VERSION ""

NS_ :

BS_:
BU_: VCU PDU CCU PCU ZCU BMS

// if the prototype battery
BO_ 512 COMMAND_FRAME_BMS: 8 VCU
  SG_ VCU_STATE_REQUEST : 5|3@1+ (1,0) [0|7] "" BMS

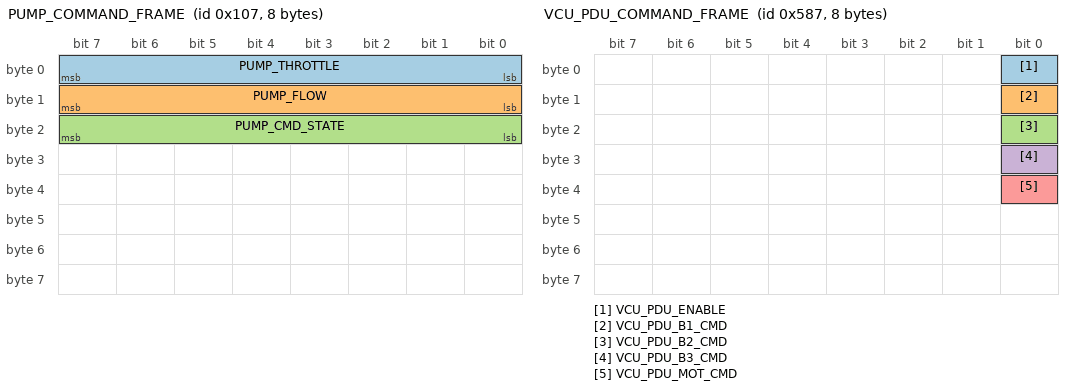
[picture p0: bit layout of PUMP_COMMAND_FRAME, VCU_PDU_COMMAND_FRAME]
BO_ 263 PUMP_COMMAND_FRAME: 8 VCU
 SG_ PUMP_THROTTLE : 0|8@1+ (1,0) [0|100] "%"  VCU
 SG_ PUMP_FLOW : 8|8@1+ (0.1,0) [0|25.5] "L/min"  VCU
 SG_ PUMP_CMD_STATE : 16|8@1+ (1,0) [0|255] ""  VCU

// if the production battery
BO_ 1264 COMMAND_FRAME_BMS: 8 VCU
  SG_ VCU_STATE_REQUEST : 5|3@1+ (1,0) [0|7] "" BMS

BO_ 1415 VCU_PDU_COMMAND_FRAME: 8 VCU
  SG_ VCU_PDU_ENABLE : 0|1@0+ (1,0) [0|1] "" PDU
  SG_ VCU_PDU_B1_CMD : 8|1@0+ (1,0) [0|1] "" PDU
  SG_ VCU_PDU_B2_CMD : 16|1@0+ (1,0) [0|1] "" PDU
  SG_ VCU_PDU_B3_CMD : 24|1@0+ (1,0) [0|1] "" PDU
  SG_ VCU_PDU_MOT_CMD : 32|1@0+ (1,0) [0|1] "" PDU

BO_ 1543 CCU_ZCU_COMMAND_FRAME: 8 VCU
 SG_ CCU_CMD : 0|8@1+ (1,0) [0|1] ""  VCU

BO_ 1831 VCU_PCU_COMMAND_FRAME: 8 VCU
 SG_ VCU_PCU_DERATING_MODE : 0|1@1+ (1,0) [0|1] ""  PCU
 SG_ VCU_PCU_MAINTENANCE_MODE : 1|1@1+ (1,0) [0|1] ""  PCU
 SG_ VCU_PCU_MODE_ECO_SPORT : 2|1@1+ (1,0) [0|1] ""  PCU
 SG_ VCU_PCU_BOOST_MODE : 3|1@1+ (1,0) [0|1] ""  PCU
 SG_ VCU_PCU_BIST_mode : 4|1@1+ (1,0) [0|1] ""  PCU
 SG_ VCU_PCU_BRAKE : 5|1@1+ (1,0) [0|1] ""  PCU
 SG_ VCU_PCU_MODE_START_STOP : 6|1@1+ (1,0) [0|1] ""  PCU
 SG_ VCU_PCU_FORCED_MODE : 7|1@1+ (1,0) [0|1] ""  PCU
 SG_ VCU_PCU_CTRL_FORCEDPUMP : 8|4@1+ (1,0) [0|15] ""  PCU
 SG_ VCU_PCU_TRIM_DOWN_COMMAND : 12|1@1+ (1,0) [0|1] ""  PCU
 SG_ VCU_PCU_TRIM_UP_COMMAND : 13|1@1+ (1,0) [0|1] ""  PCU
 SG_ VCU_PCU_CTRL_JAKETRIM_SEL : 14|1@1+ (1,0) [0|1] ""  PCU
 SG_ VCU_PCU_LED : 15|1@1+ (1,0) [0|1] ""  PCU
 SG_ VCU_PCU_THROTTLE : 16|7@1+ (1,0) [0|100] "%"  PCU
 SG_ VCU_PCU_WATER_DETECTED : 23|1@1+ (1,0) [0|1] ""  PCU
 SG_ VCU_PCU_DRIVE_SELECT : 24|4@1+ (1,0) [0|15] ""  PCU
 SG_ VCU_PCU_IGN : 28|1@1+ (1,0) [0|1] ""  PCU
 SG_ VCU_PCU_DRIVE_CHARGE_STATE : 29|1@1+ (1,0) [0|1] ""  PCU
 SG_ VCU_PCU_kill : 30|1@1+ (1,0) [0|1] ""  PCU
 SG_ VCU_PCU_HVIL : 31|1@1+ (1,0) [0|1] ""  PCU
 SG_ VCU_PCU_UV_LIMIT : 32|16@1+ (0.1,0) [0|6553.5] "V"  PCU
 SG_ VCU_PCU_MAXCUR_LIMIT : 48|16@1+ (1,0) [0|65535] "A"  PCU

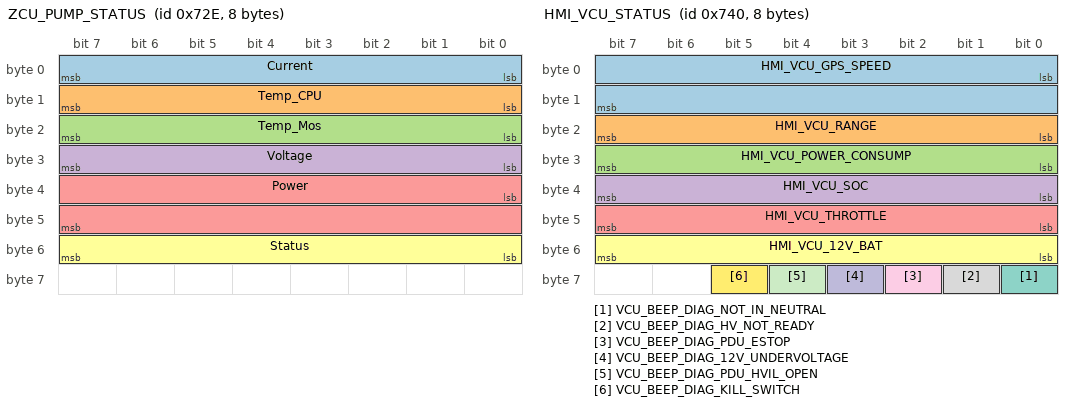
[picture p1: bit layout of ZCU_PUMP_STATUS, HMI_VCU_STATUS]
BO_ 1838 ZCU_PUMP_STATUS: 8 ZCU
 SG_ Current : 0|8@1+ (0.2,0) [0|50.8] "A" Vector__XXX
 SG_ Temp_CPU : 8|8@1+ (1,40) [-40|215] "°C" Vector__XXX
 SG_ Temp_Mos : 16|8@1+ (1,40) [-40|215] "°C" Vector__XXX
 SG_ Voltage : 24|8@1+ (0.1,0) [0|25.5] "V" Vector__XXX
 SG_ Power : 32|16@1+ (0.1,0) [0|6553.5] "W" Vector__XXX
 SG_ Status : 48|8@1+ (1,0) [0|255] "" Vector__XXX

BO_ 1856 HMI_VCU_STATUS: 8 VCU
  SG_ HMI_VCU_GPS_SPEED : 0|16@1+ (0.02302,0) [0|100] "MPH" Vector__XXX
  SG_ HMI_VCU_RANGE : 16|8@1+ (1,0) [0|300] "NM" Vector__XXX
  SG_ HMI_VCU_POWER_CONSUMP : 24|8@1+ (0.1,0) [-500|500] "kW" Vector__XXX
  SG_ HMI_VCU_SOC : 32|8@1+ (1,0) [0|100] "%" Vector__XXX
  SG_ HMI_VCU_THROTTLE : 40|8@1+ (1,0) [0|100] "%" Vector__XXX
  SG_ HMI_VCU_12V_BAT : 48|8@1+ (0.1,0) [0|15] "VDC" Vector__XXX
  SG_ VCU_BEEP_DIAG_NOT_IN_NEUTRAL : 56|1@1+ (1,0) [0|1] "" Vector__XXX
  SG_ VCU_BEEP_DIAG_HV_NOT_READY : 57|1@1+ (1,0) [0|1] "" Vector__XXX
  SG_ VCU_BEEP_DIAG_PDU_ESTOP : 58|1@1+ (1,0) [0|1] "" Vector__XXX
  SG_ VCU_BEEP_DIAG_12V_UNDERVOLTAGE : 59|1@1+ (1,0) [0|1] "" Vector__XXX
  SG_ VCU_BEEP_DIAG_PDU_HVIL_OPEN : 60|1@1+ (1,0) [0|1] "" Vector__XXX
  SG_ VCU_BEEP_DIAG_KILL_SWITCH : 61|1@1+ (1,0) [0|1] "" Vector__XXX

BO_ 1408 PDU_RELAY_STATUS: 8 PDU
  SG_ PDU_B1_NEG_CMD          :  0|1@1+ (1,0) [0|1] "" VCU
  SG_ PDU_B1_NEG_STATUS       :  3|1@1+ (1,0) [0|1] "" VCU
  SG_ PDU_B1_POS_CMD          :  4|1@1+ (1,0) [0|1] "" VCU
  SG_ PDU_B1_POS_STATUS       :  7|1@1+ (1,0) [0|1] "" VCU
  SG_ PDU_B2_NEG_CMD          :  8|1@1+ (1,0) [0|1] "" VCU
  SG_ PDU_B2_NEG_STATUS       : 11|1@1+ (1,0) [0|1] "" VCU
  SG_ PDU_B2_POS_CMD          : 12|1@1+ (1,0) [0|1] "" VCU
  SG_ PDU_B2_POS_STATUS       : 15|1@1+ (1,0) [0|1] "" VCU
  SG_ PDU_B3_NEG_CMD          : 16|1@1+ (1,0) [0|1] "" VCU
  SG_ PDU_B3_NEG_STATUS       : 19|1@1+ (1,0) [0|1] "" VCU
  SG_ PDU_B3_POS_CMD          : 20|1@1+ (1,0) [0|1] "" VCU
  SG_ PDU_B3_POS_STATUS       : 23|1@1+ (1,0) [0|1] "" VCU
  SG_ PDU_MOT_NEG_CMD         : 24|1@1+ (1,0) [0|1] "" VCU
  SG_ PDU  PDU_MOT_NEG_STATUS  : 27|1@1+ (1,0) [0|1] "" VCU
  SG_ PDU_MOT_POS_CMD         : 28|1@1+ (1,0) [0|1] "" VCU
  SG_ PDU_MOT_POS_STATUS      : 31|1@1+ (1,0) [0|1] "" VCU
  SG_ PDU_PRECHG_CMD          : 44|1@1+ (1,0) [0|1] "" VCU
  SG_ PDU_MSG_COUNTER         : 56|8@1+ (1,0) [0|255] "" VCU

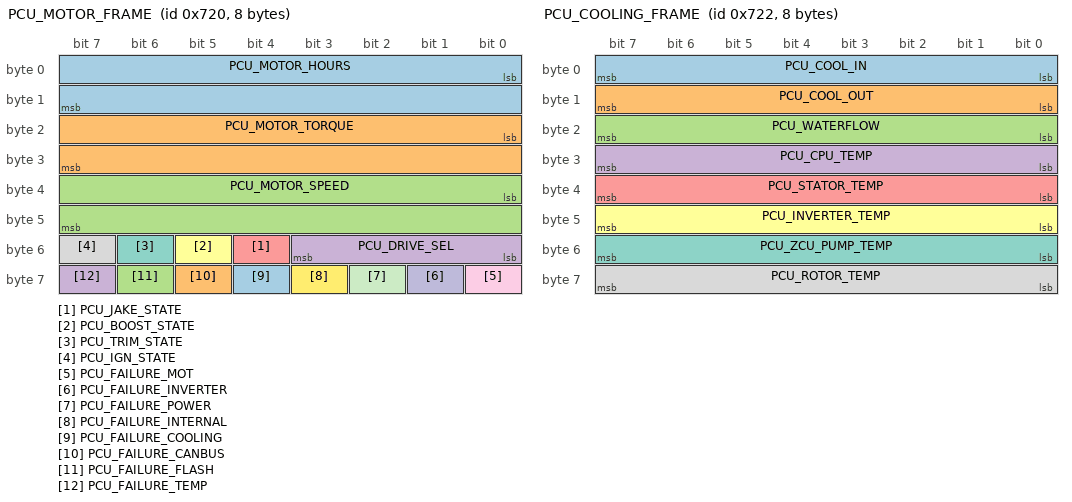
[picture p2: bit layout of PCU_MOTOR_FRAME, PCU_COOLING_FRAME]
BO_ 1824 PCU_MOTOR_FRAME: 8 PCU
  SG_ PCU_MOTOR_HOURS : 0|16@1+ (1,0) [0|10000] "h" VCU
  SG_ PCU_MOTOR_TORQUE : 16|16@1- (0.1,0) [-30000|30000] "Nm" VCU
  SG_ PCU_MOTOR_SPEED : 32|16@1+ (1,0) [0|30000] "RPM" VCU
  SG_ PCU_DRIVE_SEL : 48|4@1+ (1,0) [0|15] "" VCU
  SG_ PCU_JAKE_STATE : 52|1@1+ (1,0) [0|1] "" VCU
  SG_ PCU_BOOST_STATE : 53|1@1+ (1,0) [0|1] "" VCU
  SG_ PCU_TRIM_STATE : 54|1@1+ (1,0) [0|1] "" VCU
  SG_ PCU_IGN_STATE : 55|1@1+ (1,0) [0|1] "" VCU
  SG_ PCU_FAILURE_MOT : 56|1@1+ (1,0) [0|1] "" VCU
  SG_ PCU_FAILURE_INVERTER : 57|1@1+ (1,0) [0|1] "" VCU
  SG_ PCU_FAILURE_POWER : 58|1@1+ (1,0) [0|1] "" VCU
  SG_ PCU_FAILURE_INTERNAL : 59|1@1+ (1,0) [0|1] "" VCU
  SG_ PCU_FAILURE_COOLING : 60|1@1+ (1,0) [0|1] "" VCU
  SG_ PCU_FAILURE_CANBUS : 61|1@1+ (1,0) [0|1] "" VCU
  SG_ PCU_FAILURE_FLASH : 62|1@1+ (1,0) [0|1] "" VCU
  SG_ PCU_FAILURE_TEMP : 63|1@1+ (1,0) [0|1] "" VCU

BO_ 1826 PCU_COOLING_FRAME: 8 PCU
  SG_ PCU_COOL_IN : 0|8@1+ (1,-40) [-40|215] "Celcius" VCU
  SG_ PCU_COOL_OUT : 8|8@1+ (1,-40) [-40|215] "Celcius" VCU
  SG_ PCU_WATERFLOW : 16|8@1+ (0.1,0) [0|25.5] "LPM" VCU
  SG_ PCU_CPU_TEMP : 24|8@1+ (1,-40) [-40|215] "Celcius" VCU
  SG_ PCU_STATOR_TEMP : 32|8@1+ (1,-40) [-40|215] "Celcius" VCU
  SG_ PCU_INVERTER_TEMP : 40|8@1+ (1,-40) [-40|215] "Celcius" VCU
  SG_ PCU_ZCU_PUMP_TEMP : 48|8@1+ (1,-40) [-40|215] "Celcius" VCU
  SG_ PCU_ROTOR_TEMP : 56|8@1+ (1,-40) [-40|215] "Celcius" VCU

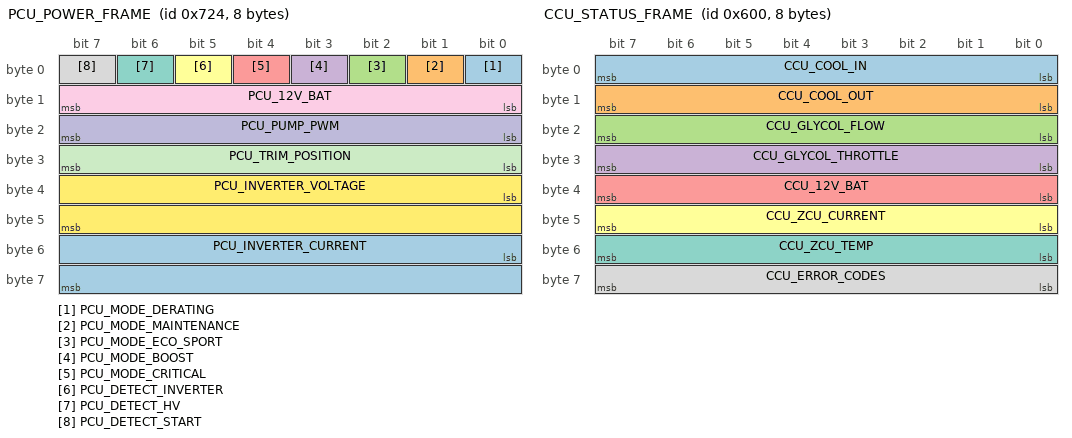
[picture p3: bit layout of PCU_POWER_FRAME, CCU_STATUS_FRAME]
BO_ 1828 PCU_POWER_FRAME: 8 PCU
  SG_ PCU_MODE_DERATING : 0|1@1+ (1,0) [0|1] "" VCU
  SG_ PCU_MODE_MAINTENANCE : 1|1@1+ (1,0) [0|1] "" VCU
  SG_ PCU_MODE_ECO_SPORT : 2|1@1+ (1,0) [0|1] "" VCU
  SG_ PCU_MODE_BOOST : 3|1@1+ (1,0) [0|1] "" VCU
  SG_ PCU_MODE_CRITICAL : 4|1@1+ (1,0) [0|1] "" VCU
  SG_ PCU_DETECT_INVERTER : 5|1@1+ (1,0) [0|1] "" VCU
  SG_ PCU_DETECT_HV : 6|1@1+ (1,0) [0|1] "" VCU
  SG_ PCU_DETECT_START : 7|1@1+ (1,0) [0|1] "" VCU
  SG_ PCU_12V_BAT : 8|8@1+ (0.1,0) [0|25.5] "V" VCU
  SG_ PCU_PUMP_PWM : 16|8@1+ (1,0) [0|100] "%" VCU
  SG_ PCU_TRIM_POSITION : 24|8@1+ (1,0) [0|100] "%" VCU
  SG_ PCU_INVERTER_VOLTAGE : 32|16@1+ (0.1,0) [0|1000] "V" VCU
  SG_ PCU_INVERTER_CURRENT : 48|16@1+ (0.1,0) [-500|500] "A" VCU

BO_ 1536 CCU_STATUS_FRAME: 8 CCU
  SG_ CCU_COOL_IN : 0|8@1+ (1,-40) [-40|215] "Celcius" VCU
  SG_ CCU_COOL_OUT : 8|8@1+ (1,-40) [-40|215] "Celcius" VCU
  SG_ CCU_GLYCOL_FLOW : 16|8@1+ (0.1,0) [0|25.5] "L/min" VCU
  SG_ CCU_GLYCOL_THROTTLE : 24|8@1+ (1,0) [0|100] "%" VCU
  SG_ CCU_12V_BAT : 32|8@1+ (1,0) [0|100] "%" VCU
  SG_ CCU_ZCU_CURRENT : 40|8@1- (0.2,0) [0|1] "A" VCU
  SG_ CCU_ZCU_TEMP : 48|8@1- (1,-40) [-40|215] "Celcius" VCU
  SG_ CCU_ERROR_CODES : 56|8@1- (1,0) [0|255] "" VCU

//BO_ 256 ZCU_PUMP_FRAME: 8 ZCU
  //SG_ ZCU_CURRENT : 0|8@1+ (5,0) [0|50.8] "A" VCU
  //SG_ ZCU_MOSFET_TEMP : 16|8@1+ (1,-40) [-40|215] "Celcius" VCU
  //SG_ ZCU_INPUT_VOLTAGE : 24|8@1+ (10,0) [0|25.5] "V" VCU
  //SG_ ZCU_POWER_CONSUMPTION : 32|16@1+ (10,0) [0|6553.5] "W" VCU
  //SG_ ZCU_CAN_TIMEOUTFLAG : 49|1@1+ (1,0) [0|1] "" VCU
  //SG_ ZCU_MODE : 51|2@1+ (1,0) [0|3] "" VCU
  //SG_ ZCU_ERROR_CODES : 56|8@1+ (1,0) [0|255] "" VCU

// ==============================================================
// ====================  BATTERY PACK MESSAGES  =================
// ==============================================================

// ---------------------  BATTERY 1 (BT1)  ---------------------
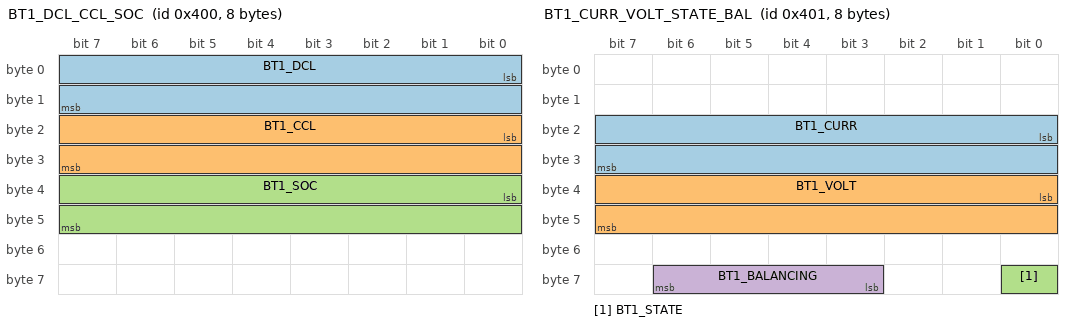
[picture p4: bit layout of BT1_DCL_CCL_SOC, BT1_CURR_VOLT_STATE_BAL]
BO_ 1024 BT1_DCL_CCL_SOC: 8 BMS
  SG_ BT1_DCL       : 0|16@1+ (0.1,0) [0|6553.5] "A"     VCU   // Discharge Current Limit
  SG_ BT1_CCL       : 16|16@1+ (0.1,0) [0|6553.5] "A"    VCU   // Charge Current Limit
  SG_ BT1_SOC       : 32|16@1+ (0.01,0) [0|100.00] "%"   VCU   // State of Charge (x100)

BO_ 1025 BT1_CURR_VOLT_STATE_BAL: 8 BMS
  SG_ BT1_CURR      : 16|16@1- (0.1,0) [-3276|3276] "A"   VCU   // Current (x10)
  SG_ BT1_VOLT      : 32|16@1+ (0.1,0) [0|655.3] "V"      VCU   // Voltage (x10)
  SG_ BT1_STATE     : 56|1@1+ (1,0) [0|1] ""              VCU   // Bit 0 of byte 7
  SG_ BT1_BALANCING : 59|4@1+ (1,0) [0|15] ""             VCU   // Bits 3–6 of byte 7

BO_ 1027 BT1_TEMP: 8 BMS
  SG_ BT1_TEMP      : 24|8@1+ (1,-40) [-40|87] "°C"       VCU   // Max cell temp

BO_ 1030 BT1_FAILURE: 8 BMS
  SG_ BT1_FAILURE   : 0|8@1+ (1,0) [0|255] ""            VCU   // Alarms

BO_ 1029 BT1_RISO: 8 BMS
  SG_ BT1_RISO      : 24|8@1+ (1,0) [0|180] "cells"      VCU   // Cells balanced

// ---------------------  BATTERY 2 (BT2)  ---------------------
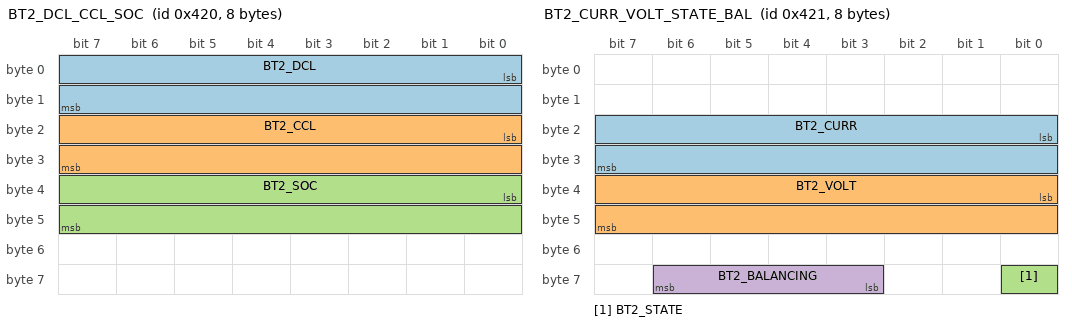
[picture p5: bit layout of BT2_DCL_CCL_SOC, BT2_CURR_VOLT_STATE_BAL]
BO_ 1056 BT2_DCL_CCL_SOC: 8 BMS
  SG_ BT2_DCL       : 0|16@1+ (0.1,0) [0|6553.5] "A"     VCU
  SG_ BT2_CCL       : 16|16@1+ (0.1,0) [0|6553.5] "A"    VCU
  SG_ BT2_SOC       : 32|16@1+ (0.01,0) [0|100.00] "%"   VCU

BO_ 1057 BT2_CURR_VOLT_STATE_BAL: 8 BMS
  SG_ BT2_CURR      : 16|16@1- (0.1,0) [-3276|3276] "A"   VCU
  SG_ BT2_VOLT      : 32|16@1+ (0.1,0) [0|655.3] "V"      VCU
  SG_ BT2_STATE     : 56|1@1+ (1,0) [0|1] ""              VCU
  SG_ BT2_BALANCING : 59|4@1+ (1,0) [0|15] ""             VCU

BO_ 1059 BT2_TEMP: 8 BMS
  SG_ BT2_TEMP      : 24|8@1+ (1,-40) [-40|87] "°C"       VCU

BO_ 1062 BT2_FAILURE: 8 BMS
  SG_ BT2_FAILURE   : 0|8@1+ (1,0) [0|255] ""            VCU

BO_ 1285 BT2_RISO: 8 BMS   // 0x505 = 1285
  SG_ BT2_RISO      : 24|8@1+ (1,0) [0|180] "cells"      VCU

// ---------------------  BATTERY 3 (BT3)  ---------------------
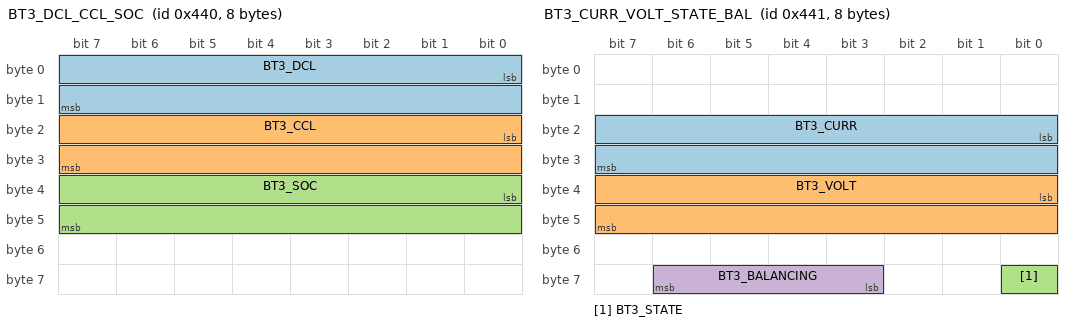
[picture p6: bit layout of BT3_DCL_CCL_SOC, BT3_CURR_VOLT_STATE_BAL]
BO_ 1088 BT3_DCL_CCL_SOC: 8 BMS
  SG_ BT3_DCL       : 0|16@1+ (0.1,0) [0|6553.5] "A"     VCU
  SG_ BT3_CCL       : 16|16@1+ (0.1,0) [0|6553.5] "A"    VCU
  SG_ BT3_SOC       : 32|16@1+ (0.01,0) [0|100.00] "%"   VCU

BO_ 1089 BT3_CURR_VOLT_STATE_BAL: 8 BMS
  SG_ BT3_CURR      : 16|16@1- (0.1,0) [-3276|3276] "A"   VCU
  SG_ BT3_VOLT      : 32|16@1+ (0.1,0) [0|655.3] "V"      VCU
  SG_ BT3_STATE     : 56|1@1+ (1,0) [0|1] ""              VCU
  SG_ BT3_BALANCING : 59|4@1+ (1,0) [0|15] ""             VCU

BO_ 1091 BT3_TEMP: 8 BMS
  SG_ BT3_TEMP      : 24|8@1+ (1,-40) [-40|87] "°C"       VCU

BO_ 1094 BT3_FAILURE: 8 BMS
  SG_ BT3_FAILURE   : 0|8@1+ (1,0) [0|255] ""            VCU

BO_ 1541 BT3_RISO: 8 BMS   // 0x605 = 1541
  SG_ BT3_RISO      : 24|8@1+ (1,0) [0|180] "cells"      VCU

CM_ SG_ 1856 VCU_BEEP_DIAG_NOT_IN_NEUTRAL "Beeping because not in neutral when attempting HV transition";
CM_ SG_ 1856 VCU_BEEP_DIAG_HV_NOT_READY "Beeping because HV < 60V or transitioning";
CM_ SG_ 1856 VCU_BEEP_DIAG_PDU_ESTOP "Beeping because PDU E-stop (contactor mismatch confirmed)";
CM_ SG_ 1856 VCU_BEEP_DIAG_12V_UNDERVOLTAGE "Beeping because 12V undervoltage heading to shutdown";
CM_ SG_ 1856 VCU_BEEP_DIAG_PDU_HVIL_OPEN "Beeping because PDU HVIL opened";
CM_ SG_ 1856 VCU_BEEP_DIAG_KILL_SWITCH "Beeping because kill switch active or TCU timeout";
// ==============================================================
// ====================  SIGNAL GROUPS (TABS)  =================
// ==============================================================

// =====================  VALUE TABLES  =========================
